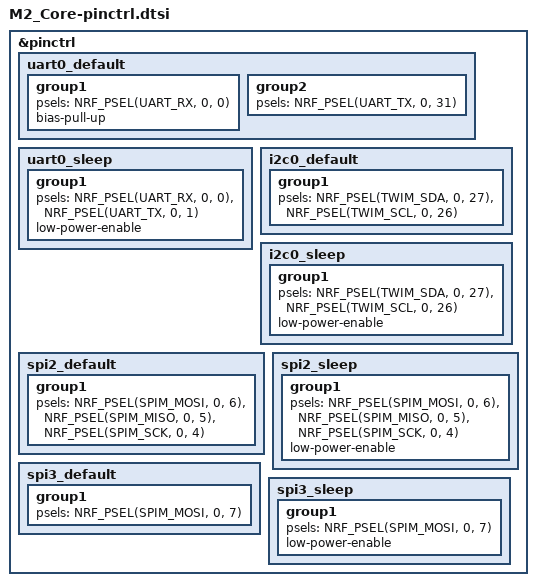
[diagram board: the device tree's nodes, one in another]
/*
* Copyright (c) 2022 The ZMK Contributors
* SPDX-License-Identifier: MIT
*/
&pinctrl {
        uart0_default: uart0_default {
                group1 {
                        psels = <NRF_PSEL(UART_RX, 0, 0)>;
                        bias-pull-up;
                };
                group2 {
                        psels = <NRF_PSEL(UART_TX, 0, 31)>;
                };
        };

        uart0_sleep: uart0_sleep {
                group1 {
                        psels = <NRF_PSEL(UART_RX, 0, 0)>,
                                <NRF_PSEL(UART_TX, 0, 1)>;
                        low-power-enable;
                };
        };

        i2c0_default: i2c0_default {
            group1 {
                    psels = <NRF_PSEL(TWIM_SDA, 0, 27)>,
                            <NRF_PSEL(TWIM_SCL, 0, 26)>;
            };
        };

        i2c0_sleep: i2c0_sleep {
            group1 {
                    psels = <NRF_PSEL(TWIM_SDA, 0, 27)>,
                            <NRF_PSEL(TWIM_SCL, 0, 26)>;
                    low-power-enable;
            };
        };
        spi2_default: spi2_default {
            group1 {
                psels = <NRF_PSEL(SPIM_MOSI, 0, 6)>,
                		<NRF_PSEL(SPIM_MISO, 0, 5)>,
                		<NRF_PSEL(SPIM_SCK, 0, 4)>;
            };
        };

        spi2_sleep: spi2_sleep {
            group1 {
                psels = <NRF_PSEL(SPIM_MOSI, 0, 6)>,
                		<NRF_PSEL(SPIM_MISO, 0, 5)>,
                		<NRF_PSEL(SPIM_SCK, 0, 4)>;
                low-power-enable;
            };
        };
        spi3_default: spi3_default {
            group1 {
                psels = <NRF_PSEL(SPIM_MOSI, 0, 7)>;
            };
        };

        spi3_sleep: spi3_sleep {
            group1 {
                psels = <NRF_PSEL(SPIM_MOSI, 0, 7)>;
                low-power-enable;
            };
        };
};
